# HR_C7000_DM32 register map
Vendor: Dahua Technology (chip); Baofeng (radio product); Series: HR_C7000; File version: 0.1-dm32re-draft
CPU: other r0p0, little endian, no MPU, no FPU, 0 interrupt priority bits
Registers are 32-bit, read-write, reset 0x0 unless marked. A register's access mark holds for its fields unless they carry their own. Offsets are from the block's base; [hi:lo] are bit positions; {n}, {i} and the like mark numbered series; <NAME> marks a mode.

## SystemControl — Baseband/modem system control and clock manager, 64 KB window at 0x11000000 (memory map, v2.2 manual p.10). Registers from several datasheet chapters share this window: soft reset (DS §4.1), clock manager (§4.2), system control and pad mux (§4.4), baseband system control (§4.6, Register Table 4 p.144-146), DMR physical layer (§9.2, Register Table 27 p.490-492), DMR link layer (§10.2, Register Table 28 p.526-527) and FM (§11.2). HAND-MAINTAINED and not yet complete: the datasheet also lists IOMGR_REN_REG1 (0x44), IOMGR_IE_IE0-2 (0x4c-0x54), RTC_REQ_HOLD (0x58), RECV_INFO_COUNT (0x164), RECVFIR_COEF1-17 (0x16c-0x1ac), PHY_RECEIVE_STATE (0x1c0), LAYER2_MAX_CNT (0x410), LAYER2_BS_MODE (0x428), BS_SECOND_REG (0x430), BS_STATUS (0x434), BS_CACH (0x438), FM_SQL (0x508), USER_DEFINE_CTC (0x51c), CDCSS_ADDR (0x520), XTCSS_ADDR (0x52c), FM_FUNCTION_COEF1-8 (0x530-0x54c), FM_DECODE_FLAG1 (0x564) and FM_ADDR_SW (0x56c), which are not described here (their offsets fall inside the RESERVED gaps). Three registers (REG_0x168, REG_0x370-REG_0x37c, INTERP_CLEAR_AUX) are not in the datasheet and come from the stock firmware writing them; they are named by offset or by placeholder.
Base 0x11000000
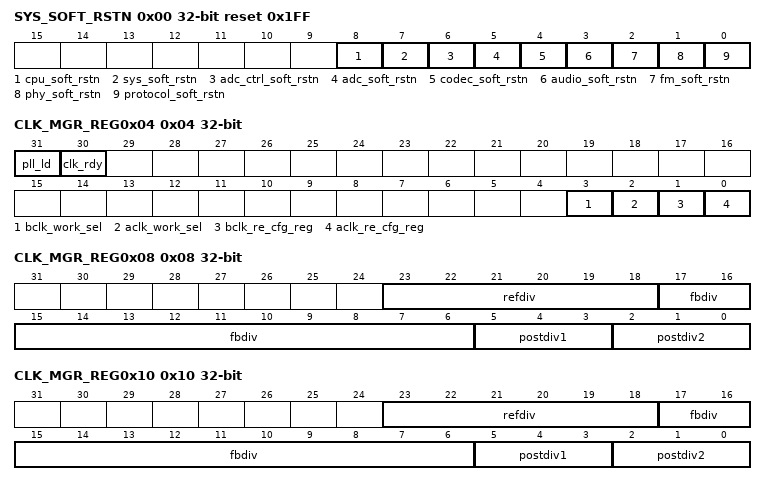
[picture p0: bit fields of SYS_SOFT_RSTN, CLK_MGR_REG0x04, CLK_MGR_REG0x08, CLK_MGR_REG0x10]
0x00 SYS_SOFT_RSTN reset 0x1FF — Per-module soft reset. DS §4.1.4.1 p.70. Writing 0 to a bit resets that module; the bit then returns to 1 by itself (self-clearing pulse, DS §4.1.2).
  [8] cpu_soft_rstn — CPU soft reset, low-active, self-clearing
  [7] sys_soft_rstn — System global soft reset, low-active, self-clearing
  [6] adc_ctrl_soft_rstn — Built-in CPU IP ADC soft reset, low-active, self-clearing
  [5] adc_soft_rstn — Built-in baseband IP ADC soft reset, low-active, self-clearing
  [4] codec_soft_rstn — Built-in IP CODEC soft reset, low-active, self-clearing
  [3] audio_soft_rstn — Audio interface module soft reset, low-active, self-clearing
  [2] fm_soft_rstn — FM module soft reset, low-active, self-clearing
  [1] phy_soft_rstn — Physical layer module soft reset, low-active, self-clearing
  [0] protocol_soft_rstn — Protocol layer module soft reset, low-active, self-clearing
0x04 CLK_MGR_REG0x04 — Top-level PLL / clock-switch control. DS §4.2.5.1 p.78. The stock boot clock init (IRAM 0x12480) busy-waits until bits [31:30] read 1 (dm32uv-qemu hw/misc/dm32_sysreg.c models this).
  [31] pll_ld ro — Combined PLL-A/PLL-B lock flag (RO)
  [30] clk_rdy ro — Clock-switch-ready flag (RO)
  [3] bclk_work_sel — SOC system clock source select: 0=PLL, 1=oscillator (default: oscillator)
  [2] aclk_work_sel — Baseband/modem system clock source select: 0=PLL, 1=oscillator
  [1] bclk_re_cfg_reg — SOC system PLL reconfiguration-ready flag, set by CPU
  [0] aclk_re_cfg_reg — Baseband/modem PLL reconfiguration-ready flag, set by CPU
0x08 CLK_MGR_REG0x08 — APLL configuration. DS §4.2.5.2 p.79. The divider fields below are transcribed; the lock, power-down, DSM/DAC power-down and bypass bits in [31:24] are not yet transcribed here.
  [23:18] refdiv — APLL reference divider (default 0x1)
  [17:6] fbdiv — APLL feedback divider (default 0x3a = 58)
  [5:3] postdiv1 — APLL post-divider 1 (default 0x6)
  [2:0] postdiv2 — APLL post-divider 2 (default 0x2)
0x0C CLK_MGR_REG0x0c reset 0xFB7E91 — APLL fractional divider (apll_frac). DS §4.2.5.3 p.81.
  [23:0] apll_frac — APLL fractional-mode divider value
0x10 CLK_MGR_REG0x10 — BPLL configuration, same layout as CLK_MGR_REG0x08. DS §4.2.5.4 p.81. Upper control bits not yet transcribed here.
  [23:18] refdiv — BPLL reference divider (default 0x2)
  [17:6] fbdiv — BPLL feedback divider (default 0x28 = 40)
  [5:3] postdiv1 — BPLL post-divider 1 (default 0x2)
  [2:0] postdiv2 — BPLL post-divider 2 (default 0x2)
0x14 CLK_MGR_REG0x14 — BPLL fractional divider (bpll_frac). DS §4.2.5.5 p.82.
  [23:0] bpll_frac — BPLL fractional-mode divider value
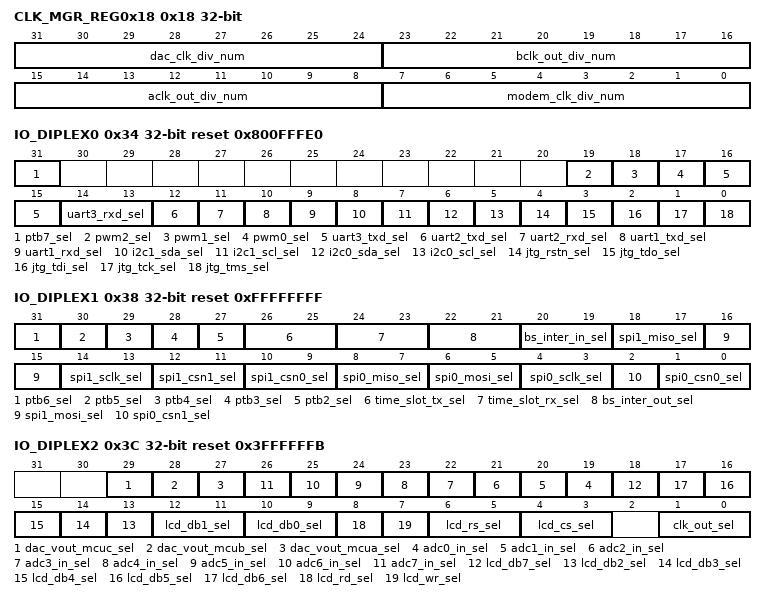
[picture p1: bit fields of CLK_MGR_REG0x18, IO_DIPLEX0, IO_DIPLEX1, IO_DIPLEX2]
0x18 CLK_MGR_REG0x18 — Per-domain output clock divider numerators. DS §4.2.5.6 p.83.
  [31:24] dac_clk_div_num — DAC clock divider numerator (default 0x10)
  [23:16] bclk_out_div_num — SOC output clock divider numerator (default 0xa)
  [15:8] aclk_out_div_num — Baseband/modem output clock divider numerator (default 0xc)
  [7:0] modem_clk_div_num — Modem clock divider numerator (default 0xc)
0x1C CLK_MGR_REG0x1c — Fractional dividers for the 32 kHz and 192 kHz clocks (denominator/numerator pairs). DS §4.2.5.7 p.83. Bit ranges not yet transcribed here; no fields defined.
0x20 CLK_MGR_REG0x20 — Codec MCLK source select (mclk_sel_reg) and divider (mclk_div_num: 24 MHz / (mclk_div_num + 1)), plus the 8 kHz and 512 kHz fractional dividers. DS §4.2.5.8 p.83. Bit ranges not yet transcribed here.
0x24 CLK_MGR_REG0x24 — CPU-side DAC/ADC clock dividers, SDIO clock delay tuning (sdio_clk_dly_reg_drv/_sample), AHB:APB ratio (apb_clk_div_num: 0 = 1:1, 1 = 1:2, 2 = 1:4) and AHB:CPU ratio (cpu_clk_ratio_reg: 0 = 1:1, 1 = 1:2). DS §4.2.5.9 p.84. Bit positions not yet transcribed here.
0x28 CLK_MGR_REG0x28 — SDIO clock divider (from a doubled 96 MHz clock) and USB 48 MHz divider. DS §4.2.5.10 p.85. Bit ranges not yet transcribed here.
0x2C CLK_MGR_REG0x2c — Clock-gate enables. DS §4.2.5.11 p.86. Field names: dac_clk_en, adc_clk_en, hclk_en, pclk_en, sdio_hclk_en, sdio_clk_en, usb_hclk_en, usb_clk_en, mc_clk_en, modem_clk_rx_en, modem_clk_tx_en, modem_clk_fmrx_en, modem_clk_fmtx_en, clk_512k_en_reg, clk_8k_en_reg, bclk_out_en_reg, aclk_out_en_reg. Bit positions not yet transcribed here.
0x30 LCSFC_BAUDR — Program-flash controller (LCSFC) SPI SCLK divider, lcsfc_baudr [31:0], reset 0x4. DS §4.4.4.1 p.93.
0x34 IO_DIPLEX0 reset 0x800FFFE0 — Pad multiplexing, bank 0: JTAG, I2C0/1, UART1-3, PWM0-2 and PTB7 (AK codec ADC_SDO) pads. DS §4.4.4.4 p.93. General rule (DS §4.4.4.4-4.4.4.6): each field's all-ones value selects the pad's GPIO function (GPIO_PTxN = bank x, bit N) and each field resets to it, except the five JTAG selects [4:0], which reset to 0 = JTAG; setting them loses the JTAG port. A pad must be switched away from GPIO before its peripheral sees it.
  [31] ptb7_sel — PTB7 multiplexing selection. 1: GPIO1_PTB7; 0: AK_ADC_SDO. (GPIO1_PTB7 = GPIOB bit 7.) [reset 0x1]
  [19] pwm2_sel — PWM_2 multiplexing selection. 1: GPIO_PTA17; 0: PWM_2 [reset 0x1]
  [18] pwm1_sel — PWM_1 multiplexing selection. 1: GPIO_PTA16; 0: PWM_1 [reset 0x1]
  [17] pwm0_sel — PWM_0 multiplexing selection. 1: GPIO_PTA15; 0: PWM_0 [reset 0x1]
  [16:15] uart3_txd_sel — UART3_TXD multiplexing selection. 3: GPIO_PTA14; 2: Reserved; 1: Baseband rf_rx_inter; 0: UART3_TXD [reset 0x3]
  [14:13] uart3_rxd_sel — UART3_RXD multiplexing selection. 3: GPIO_PTA13; 2: Reserved; 1: Baseband rf_tx_inter; 0: UART3_RXD [reset 0x3]
  [12] uart2_txd_sel — UART2_TXD multiplexing selection. 1: GPIO_PTA12; 0: UART2_TXD [reset 0x1]
  [11] uart2_rxd_sel — UART2_RXD multiplexing selection. 1: GPIO_PTA11; 0: UART2_RXD [reset 0x1]
  [10] uart1_txd_sel — UART1_TXD multiplexing selection. 1: GPIO_PTA10; 0: UART1_TXD [reset 0x1]
  [9] uart1_rxd_sel — UART1_RXD multiplexing selection. 1: GPIO_PTA9; 0: UART1_RXD [reset 0x1]
  [8] i2c1_sda_sel — I2C_SDA_1 multiplexing selection. 1: GPIO_PTA8; 0: I2C_SDA_1 [reset 0x1]
  [7] i2c1_scl_sel — I2C_SCL_1 multiplexing selection. 1: GPIO_PTA7; 0: I2C_SCL_1 [reset 0x1]
  [6] i2c0_sda_sel — I2C_SDA_0 multiplexing selection. 1: GPIO_PTA6; 0: I2C_SDA_0 [reset 0x1]
  [5] i2c0_scl_sel — I2C_SCL_0 multiplexing selection. 1: GPIO_PTA5; 0: I2C_SCL_0 [reset 0x1]
  [4] jtg_rstn_sel — JTG_RST_N multiplexing selection. 1: GPIO_PTA4; 0: JTG_RST_N [reset 0x0]
  [3] jtg_tdo_sel — JTG_TDO multiplexing selection. 1: GPIO_PTA3; 0: JTG_TDO [reset 0x0]
  [2] jtg_tdi_sel — JTG_TDI multiplexing selection. 1: GPIO_PTA2; 0: JTG_TDI [reset 0x0]
  [1] jtg_tck_sel — JTG_TCK multiplexing selection. 1: GPIO_PTA1; 0: JTG_TCK [reset 0x0]
  [0] jtg_tms_sel — JTG_TMS multiplexing selection. 1: GPIO_PTA0; 0: JTG_TMS [reset 0x0]
0x38 IO_DIPLEX1 reset 0xFFFFFFFF — Pad multiplexing, bank 1: SPI0/SPI1 (with SDIO alternates), the baseband TIME_SLOT/BS_INTER lines and PTB2-PTB6 (AK codec ADC/DAC serial pads). DS §4.4.4.5 p.97. FW: hr_c7000_modem_core_clock_and_reset_init @0x0301d5f8 sets bits 27-29 (|= 0x38000000: PTB2-PTB4 to GPIO).
  [31] ptb6_sel — PTB6 multiplexing selection. 1: GPIO1_PTB6; 0: AK_ADC_SCLK [reset 0x1]
  [30] ptb5_sel — PTB4 multiplexing selection. 1: GPIO1_PTB5; 0: AK_ADC_FS. The guide prints this row's name as 'PTB4', a typo for PTB5 (the GPIO it selects is PTB5). [reset 0x1]
  [29] ptb4_sel — PTB4 multiplexing selection. 1: GPIO1_PTB4; 0: AK_DAC_SDI [reset 0x1]
  [28] ptb3_sel — PTB3 multiplexing selection. 1: GPIO1_PTB3; 0: AK_DAC_SCLK [reset 0x1]
  [27] ptb2_sel — PTB2 multiplexing selection. 1: GPIO1_PTB2; 0: AK_DAC_FS [reset 0x1]
  [26:25] time_slot_tx_sel — TIME_SLOT_T_INTER multiplexing selection. 3: GPIO_PTA31; 2: SDIO sdio_card_write_prt; 1: Reserved; 0: TIME_SLOT_T_INTER [reset 0x3]
  [24:23] time_slot_rx_sel — TIME_SLOT_R_INTER multiplexing selection. 3: GPIO_PTA30; 2: SDIO sdio_card_detect_n; 1: Reserved; 0: TIME_SLOT_R_INTER [reset 0x3]
  [22:21] bs_inter_out_sel — BS_INTER_OUT multiplexing selection. 3: GPIO_PTA29; 2: SDIO sdio_cdata[1]; 1: Reserved; 0: BS_INTER_OUT [reset 0x3]
  [20:19] bs_inter_in_sel — BS_INTER_IN multiplexing selection. 3: GPIO_PTA28; 2: SDIO sdio_cdata[2]; 1: POR_RST_N; 0: BS_INTER_IN [reset 0x3]
  [18:17] spi1_miso_sel — SPI1_MISO multiplexing selection. 3: GPIO_PTA27; 2: SDIO sdio_cdata[0]; 1: Slave SPI1_MISO; 0: Master SPI1_MISO [reset 0x3]
  [16:15] spi1_mosi_sel — SPI1_MOSI multiplexing selection. 3: GPIO_PTA26; 2: SDIO sdio_ccmd; 1: Slave SPI1_MOSI; 0: Master SPI1_MOSI [reset 0x3]
  [14:13] spi1_sclk_sel — SPI1_SCLK multiplexing selection. 3: GPIO_PTA25; 2: SDIO sdio_cclk_out; 1: Slave SPI1_SCLK; 0: Master SPI1_SCLK [reset 0x3]
  [12:11] spi1_csn1_sel — SPI1_CSN_1 multiplexing selection. 3: GPIO_PTA24; 2: Reserved; 1: Baseband sys_inter; 0: Master SPI1_CSN_1 [reset 0x3]
  [10:9] spi1_csn0_sel — SPI1_CSN_0 multiplexing selection. 3: GPIO_PTA23; 2: SDIO sdio_cdata[3]; 1: Slave SPI1_CSN_0; 0: Master SPI1_CSN_0 [reset 0x3]
  [8:7] spi0_miso_sel — SPI0_MISO multiplexing selection. 3: GPIO_PTA22; 2: Reserved; 1: Slave SPI0_MISO; 0: Master SPI0_MISO [reset 0x3]
  [6:5] spi0_mosi_sel — SPI0_MOSI multiplexing selection. 3: GPIO_PTA21; 2: Reserved; 1: Slave SPI0_MOSI; 0: Master SPI0_MOSI [reset 0x3]
  [4:3] spi0_sclk_sel — SPI0_SCLK multiplexing selection. 3: GPIO_PTA20; 2: Reserved; 1: Slave SPI0_SCLK; 0: Master SPI0_SCLK [reset 0x3]
  [2] spi0_csn1_sel — SPI0_CSN_1 multiplexing selection. 1: GPIO_PTA19; 0: SPI0_CSN_1 [reset 0x1]
  [1:0] spi0_csn0_sel — SPI0_CSN_0 multiplexing selection. 3: GPIO_PTA18; 2: Reserved; 1: Slave SPI0_CSN_0; 0: Master SPI0_CSN_0 [reset 0x3]
0x3C IO_DIPLEX2 reset 0x3FFFFFFB — Pad multiplexing, bank 2: CLK_OUT, the LCD bus (CS/RS/WR/RD, DB0-DB7; CS/RS/DB0/DB1 also SPI2), ADC0-7 inputs and DAC_VOUT_MCUA-C. DS §4.4.4.6 p.101. FW: every stock keypad scan (keypad_scan_and_map_pressed_key @0x03013660) first calls 0x03012e14, which sets IO_DIPLEX2 |= 0xfe00 (LCD_DB0-DB4 pads = GPIOC 7-11 to GPIO, to drive the keypad lines); lcd_bus_restore_after_keypad_scan @0x0301cad0 undoes it with &= 0xffff01ff, and the panel init lcd_controller_power_on_init_sequence @0x03017d4c claims the panel pads with &= 0xfff80107 (literal at 0x03017f4c). An LCD write while DB0-DB4 are muxed to GPIO misses the panel (observed on hardware: the panel stays white until power-cycled).
  [29] dac_vout_mcuc_sel — DAC_VOUT_MCUC multiplexing selection. 1: GPIO_PTC25; 0: DAC_VOUT_MCUC [reset 0x1]
  [28] dac_vout_mcub_sel — DAC_VOUT_MCUB multiplexing selection. 1: GPIO_PTC24; 0: DAC_VOUT_MCUB [reset 0x1]
  [27] dac_vout_mcua_sel — DAC_VOUT_MCUA multiplexing selection. 1: GPIO_PTC23; 0: DAC_VOUT_MCUA [reset 0x1]
  [n+19] adc{n}_in_sel (n=0..7) — ADC{n}_IN multiplexing selection. 1: GPIO_PTC{n+15}; 0: ADC{n}_IN [reset 0x1]
  [18] lcd_db7_sel — LCD_DB7 multiplexing selection. 1: GPIO_PTC24; 0: LCD_DB7. The guide prints GPIO_PTC24, which bit 28 also claims; the pattern of the neighbouring rows gives GPIO_PTC14 (INFERRED). [reset 0x1]
  [n+11] lcd_db{n}_sel (n=2..6) — LCD_DB{n} multiplexing selection. 1: GPIO_PTC{n+7}; 0: LCD_DB{n} [reset 0x1]
  [12:11] lcd_db1_sel — LCD_DB1 multiplexing selection. 3: GPIO_PTC8; 2: Slave SPI2_MOSI; 1: Master SPI2_MOSI; 0: LCD_DB1 [reset 0x3]
  [10:9] lcd_db0_sel — LCD_DB0 multiplexing selection. 3: GPIO_PTC7; 2: Slave SPI2_MISO; 1: Master SPI2_MISO; 0: LCD_DB0 [reset 0x3]
  [8] lcd_rd_sel — LCD_RD multiplexing selection. 1: GPIO_PTC6; 0: LCD_RD [reset 0x1]
  [7] lcd_wr_sel — LCD_WR multiplexing selection. 1: GPIO_PTC5; 0: LCD_WR [reset 0x1]
  [6:5] lcd_rs_sel — LCD_RS multiplexing selection. 3: GPIO_PTC4; 2: Slave SPI2_SCLK; 1: Master SPI2_SCLK; 0: LCD_RS [reset 0x3]
  [4:3] lcd_cs_sel — LCD_CS multiplexing selection. 3: GPIO_PTC3; 2: Slave SPI2_CS; 1: Master SPI2_CS; 0: LCD_CS [reset 0x3]
  [1:0] clk_out_sel — CLK_OUT multiplexing selection. 3: GPIO_PTC0; 2: RTC_CLK; 1: PLLB CLK_OUT; 0: PLLA CLK_OUT [reset 0x3]
0x40 RESERVED_0x40 — The datasheet's IOMGR_REN_REG0 (pad pull-up enables, 1 = pull-up off, 0 = on; DS §4.4.4.7 p.105), kept under this placeholder name so existing decompiler labels stay stable; fields not transcribed here. FW: hr_c7000_modem_core_clock_and_reset_init @0x0301d5f8 clears bit 24 (spi1_csn1_ren: pull-up on) and sets bit 25 (spi1_sclk_ren: off) right after its IO_DIPLEX1 write.
0x48 RESERVED_0x48 — The datasheet's IOMGR_REN_REG2 (pad pull-up enables for PTB pads, 1 = pull-up off; DS §4.4.4.9 p.113), kept under this placeholder name; fields not transcribed here. FW: the same function as RESERVED_0x40 sets bits 27 and 26 (ptb27_ren, ptb26_ren: pull-ups off).
0x5C QUAD_ENABLE — Program-flash controller quad mode: quad_enable [0] (four-wire enable, high active) and sys_sample_delay [31:24] (input sampling delay, 0-8). DS §4.4.4.3 p.93. Fields not transcribed here.
0x70 DAC_CONTROL — Baseband DAC control (power-down, low-power mode, data format). DS §4.6.5.1 p.146. Fields not transcribed here.
0x74 ADC_CONTROL — Baseband ADC control. DS §4.6.5.2 p.146. Fields not transcribed here.
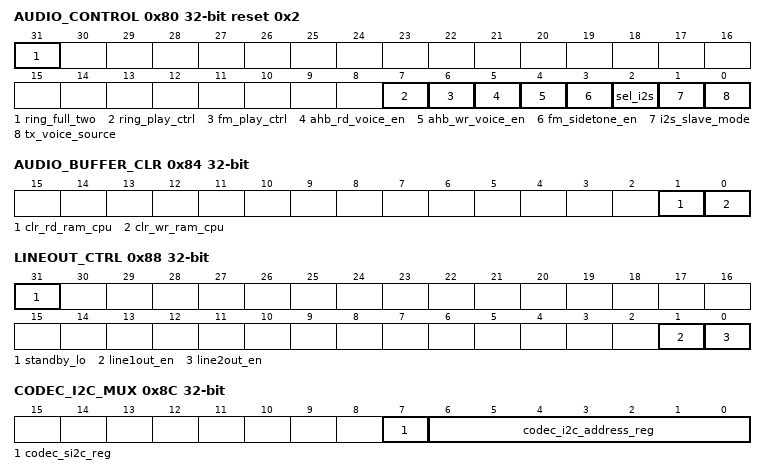
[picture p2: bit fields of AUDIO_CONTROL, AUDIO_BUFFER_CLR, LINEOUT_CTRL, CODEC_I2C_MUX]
0x80 AUDIO_CONTROL reset 0x2 — Audio path routing. DS §4.6.5.3 p.148. The stock firmware's bit-mask writes match these field names.
  [31] ring_full_two ro — Prompt-tone PCM FIFO full flag (RO); stop writing until it clears
  [7] ring_play_ctrl — Select prompt/alert-tone path, high-active
  [6] fm_play_ctrl — Select FM playback channel, high-active
  [5] ahb_rd_voice_en — AHB read-audio enable, high-active
  [4] ahb_wr_voice_en — AHB write-audio start flag, high-active
  [3] fm_sidetone_en — Analog sidetone playback enable, high-active
  [2] sel_i2s — I2S interface enable (baseband test mode)
  [1] i2s_slave_mode — Audio I2S master/slave: 0=master, 1=slave (baseband test mode). Default 1.
  [0] tx_voice_source — Voice-frame source select: 0=Codec/vocoder (normal handheld use), 1=MCU RAM (Layer-2 BS send mode)
0x84 AUDIO_BUFFER_CLR — Vocoder encode/decode buffer clear. DS §4.6.5.4 p.150. Both bits are write-1-to-clear and release themselves.
  [1] clr_rd_ram_cpu — Write 1 to clear the vocoder DECODE buffer; self-clears
  [0] clr_wr_ram_cpu — Write 1 to clear the vocoder ENCODE buffer; self-clears
0x88 LINEOUT_CTRL — Codec line-out enables. DS §4.6.5.5 p.150.
  [31] standby_lo ro — Line-out standby status (RO)
  [1] line1out_en — Line-out 1 enable
  [0] line2out_en — Line-out 2 enable
0x8C CODEC_I2C_MUX — Codec control-interface select. DS §4.6.5.6 p.150.
  [7] codec_si2c_reg — Codec control interface select: 0=MC interface, 1=I2C
  [6:0] codec_i2c_address_reg — Codec I2C address (when codec_si2c_reg=1)
0x100 WORK_MODE — Baseband working mode: digital/analog, Tier I/II, continuous/timeslot, layer mode [4:3] (0 physical, 1 layer 2, 2 layer 3), repeater, alignment, working slot. DS §4.6.5.7 p.151, §9.2.2.1 p.492 (the DMR and FM chapters repeat it). Fields not transcribed here. An emulator trace (dm32uv-qemu hw/misc/dm32_sysreg.c) saw (value & 0x18) != 0, i.e. a non-physical layer mode, when the modem entered active free-run establishment in a TX-slot self-test.
0x104 RF_MODE — Baseband RF interface mode. DS §4.6.5.8 p.152, §9.2.2.2 p.494. Fields not transcribed here.
0x108 SIG_CENTER — TX/RX IQ DC-bias setting. FW: mmio_11000108_high_word_write_from_byte @0x0302180c writes a repeated byte into the upper 16 bits (param << 24 | (param & 0xff) << 16). DS §9.2.2.3 p.496.
0x10C TX_IF_FREQ — TX IF frequency word. FW: hr_c7000_modem_core_register_init @0x03023608. DS §9.2.2.4 p.497.
0x110 RF_CONTROL — RF TX/RX interrupt advance. FW: modem_rf_mode_transition_apply @0x0301e628 ORs in 0x1a00 then 0x12, next to an RF_MODE |= 0x800 write, in one RF-mode branch. DS §9.2.2.5 p.498.
0x114 RF_MOD_BIAS_CTRL — TX signal amplitude adjustment. FW: mmio_11000114_low_word_duplicate_write @0x03021830 writes (param & 0xff) * 0x101 into the low 16 bits. DS §9.2.2.6 p.498.
0x118 DEV_LIMITER — TX frequency-deviation threshold. FW: hr_c7000_modem_core_register_init @0x03023608, FUN_00016b60. DS §9.2.2.7 p.498.
0x11C RSSI_BIAS_VALUE — Signal-energy detection value and ADC DC-bias detection. FW: hr_c7000_modem_core_register_init @0x03023608, FUN_030c6780. DS §9.2.2.8 p.498.
0x120 THRESHOLD_VALUE — Sync-detection threshold. FW: hr_c7000_modem_core_register_init @0x03023608. DS §9.2.2.9 p.499.
0x128 PHASE_OUT — Phase-input amplitude detection in AF receive mode. DS §9.2.2.10 p.500.
0x12C SEND_DATA_SYNC_H — TX data sync pattern, high half. FW: modem_rf_mode_transition_apply @0x0301e628 loads SEND_DATA_SYNC_H/L as a pair from one of two 2-word tables (literal-pool slots 0x0301e890 and 0x0301e738), depending on the mode. DS §9.2.2.11 p.500.
0x130 SEND_DATA_SYNC_L — TX data sync pattern, low half (see SEND_DATA_SYNC_H). DS §9.2.2.12 p.500.
0x134 SEND_RC_SYNC_H — TX RC (reverse channel) sync pattern, high half. DS §9.2.2.13 p.502.
0x138 SEND_RC_SYNC_L — TX RC sync pattern, low half. DS §9.2.2.14 p.502.
0x13C RECV_MS_SYNC_H — RX MS data sync pattern, high half. DS §9.2.2.15 p.502.
0x140 RECV_MS_SYNC_L — RX MS data sync pattern, low half. DS §9.2.2.16 p.502.
0x144 RECV_BS_SYNC_H — RX BS data sync pattern, high half. DS §9.2.2.17 p.503.
0x148 RECV_BS_SYNC_L — RX BS data sync pattern, low half. DS §9.2.2.18 p.504.
0x14C RECV_TDMA1_SYNC_H — RX TDMA1 data sync pattern, high half. DS §9.2.2.19 p.504.
0x150 RECV_TDMA1_SYNC_L — RX TDMA1 data sync pattern, low half. DS §9.2.2.20 p.504.
0x154 RECV_TDMA2_SYNC_H — RX TDMA2 data sync pattern, high half. DS §9.2.2.21 p.505.
0x158 RECV_TDMA2_SYNC_L — RX TDMA2 data sync pattern, low half. DS §9.2.2.22 p.506.
0x15C RECV_RC_SYNC_H — RX RC data sync pattern, high half. DS §9.2.2.23 p.506.
0x160 RECV_RC_SYNC_L — RX RC data sync pattern, low half. DS §9.2.2.24 p.506.
0x168 REG_0x168 — Not in the datasheet: Register Table 27 (DS §9.2.1 p.490-492) goes from RECV_INFO_COUNT (0x164) to RECVFIR_COEF1 (0x16c), and no edition lists 0x168. Its existence comes from the stock firmware, which writes it: hr_c7000_modem_core_register_init @0x03023608 stores 0x14 (0x03023760) when the RF mode is 4 and 0x98 (0x030237ba) otherwise, and radio_mode_transition_sequencer @0x03021670 stores 0x98 (0x0302172c); each store is paired with an RF_RECV_DELAY write (14000 or 0). A third-party driver header lists the same offset without a name. Role unknown; named by offset.
0x1B0 RX_IF_FREQ — RX IF frequency word. DS §9.2.2.43 p.515.
0x1B4 RF_RECV_DELAY — RX channel delay offset. FW: written with REG_0x168 (14000 in RF mode 4, else 0). DS §9.2.2.44 p.515.
0x1B8 MODEM_AK_CLK_CALB — AK2401 clock adjustment control. The section prints offset 0x1b4 (RF_RECV_DELAY's); Register Table 27 gives 0x1b8, which is used. DS §9.2.2.45 p.515.
0x1BC AK2401_ADC_STATE — AK2401 ADC receive status. DS §9.2.2.46 p.516.
0x350 PI_CRC_MASK — PI frame CRC16 mask and initial value. FW: register_init @0x03023608 writes 0x6969. DS §10.2.2.2 p.529.
0x354 RS_H_MASK — RS(12,9) code mask for the voice LC header. DS §10.2.2.3 p.529.
0x358 RS_H_INIT — RS code initial value for the voice LC header. FW: register_init writes 0. DS §10.2.2.4 p.530.
0x35C RS_T_MASK — RS code mask for the terminator. DS §10.2.2.5 p.531.
0x360 RS_T_INIT — RS code initial value for the terminator. FW: register_init writes 0. DS §10.2.2.6 p.531.
0x364 CSBK_CRC_MASK — CSBK CRC16 mask and initial value. FW: register_init writes 0xa5a5. DS §10.2.2.7 p.531.
0x368 MBCH_CRC_MASK — MBC header CRC16 mask and initial value. FW: register_init writes 0xaaaa. DS §10.2.2.8 p.531.
0x36C DATAH_CRC_MASK — Data header CRC16 mask and initial value. FW: register_init writes 0xcccc. DS §10.2.2.9 p.531.
0x370 REG_0x370 — Not in the datasheet: Register Table 28 (DS §10.2.1 p.526-527) goes from DATAH_CRC_MASK (0x36c) to CRC8_INIT (0x380), and no edition lists 0x370-0x37c. Its existence comes from the stock firmware: hr_c7000_modem_core_register_init @0x03023608 stores 0xf0 here (st32.w at 0x030236d2), in the same run of stores that initialises the CRC mask registers around it (0x370 = 0xf0, 0x374 = 0x1ff, 0x378 = 0x10f, 0x37c = 0). A third-party driver header lists 0x370-0x37c as unnamed ('???'). Role unknown; named by offset.
0x374 REG_0x374 — Not in the datasheet: Register Table 28 (DS §10.2.1 p.526-527) goes from DATAH_CRC_MASK (0x36c) to CRC8_INIT (0x380), and no edition lists 0x370-0x37c. Its existence comes from the stock firmware: hr_c7000_modem_core_register_init @0x03023608 stores 0x1ff here (st32.w at 0x030236da), in the same run of stores that initialises the CRC mask registers around it (0x370 = 0xf0, 0x374 = 0x1ff, 0x378 = 0x10f, 0x37c = 0). A third-party driver header lists 0x370-0x37c as unnamed ('???'). Role unknown; named by offset.
0x378 REG_0x378 — Not in the datasheet: Register Table 28 (DS §10.2.1 p.526-527) goes from DATAH_CRC_MASK (0x36c) to CRC8_INIT (0x380), and no edition lists 0x370-0x37c. Its existence comes from the stock firmware: hr_c7000_modem_core_register_init @0x03023608 stores 0x10f here (st32.w at 0x030236e2), in the same run of stores that initialises the CRC mask registers around it (0x370 = 0xf0, 0x374 = 0x1ff, 0x378 = 0x10f, 0x37c = 0). A third-party driver header lists 0x370-0x37c as unnamed ('???'). Role unknown; named by offset.
0x37C REG_0x37c — Not in the datasheet: Register Table 28 (DS §10.2.1 p.526-527) goes from DATAH_CRC_MASK (0x36c) to CRC8_INIT (0x380), and no edition lists 0x370-0x37c. Its existence comes from the stock firmware: hr_c7000_modem_core_register_init @0x03023608 stores 0 here (st32.w at 0x030236e6), in the same run of stores that initialises the CRC mask registers around it (0x370 = 0xf0, 0x374 = 0x1ff, 0x378 = 0x10f, 0x37c = 0). A third-party driver header lists 0x370-0x37c as unnamed ('???'). Role unknown; named by offset.
0x380 CRC8_INIT — Short LC CRC8 initial value. FW: register_init writes 0. DS §10.2.2.10 p.533.
0x384 LOCAL_CC — Local colour code for TX and RX, voice-frame EMB PI setting. DS §10.2.2.11 p.533.
0x388 VOICE_EMB_CTRL — Voice frame F EMB fill settings. FW: register_init writes 0. DS §10.2.2.12 p.533.
0x38C SCRAMBLE_REG — Basic voice-scrambling key. FW: register_init writes 0. DS §10.2.2.13 p.534.
0x390 RX_TYPE_INFO — Received frame information. DS §10.2.2.14 p.535.
0x394 RX_INFO — Received RC frame information. Register Table 28 prints offset 0x39c (SYS_INTERP_MASK's); the section gives 0x394, which is used. DS §10.2.2.15 p.537.
0x398 SYS_INTERP_LIST — System (layer-2) interrupt vector list: L2 TX/RX processing, voice access, frame info, slot faults, simulcast GPS-pulse loss, FM detect/RX/TX. The bit numbering is in the datasheet but not transcribed here. DS §4.6.5.9 p.156.
0x39C SYS_INTERP_MASK — Mask for SYS_INTERP_LIST. FW: register_init @0x03023608 writes 0x1187f. DS §4.6.5.10 p.156.
0x3A0 SYS_INTERP_CLEAR — Clear for SYS_INTERP_LIST (write 1 to clear). DS §4.6.5.11 p.160.
0x3A4 LAYER3_INTERP_LIST — Layer-3 interrupt vector list: call reject/timeout, OACSU, voice TX start/end/EMB/key update, SMS TX/RX (CRC32 error/ok), repeater short LC. Bit numbering not transcribed here. DS §4.6.5.12 p.160.
0x3A8 LAYER3_INTERP_MASK — Mask for LAYER3_INTERP_LIST. DS §4.6.5.13 p.162.
0x3AC LAYER3_INTERP_CLEAR — Clear for LAYER3_INTERP_LIST. DS §4.6.5.14 p.165.
0x3B0 INTERP_CLEAR — Clear for the 30 ms, RF and PCM interrupts. DS §4.6.5.15 p.166. Bit 0 is transcribed; the datasheet gives seven fields. FW: the TX-slot ISR (IRAM 0x2c42c) writes bit 0 before posting its semaphore (also modelled in dm32uv-qemu hw/misc/dm32_sysreg.c).
  [0] clear_time_txslot_inter — Write 1 to acknowledge/clear the TX-slot-wrap interrupt (PIC source 30)
0x3B4 INTERP_CLEAR_AUX — Not in the datasheet (Register Table 4 ends at INTERP_CLEAR, 0x3b0) and not in any third-party header; placeholder name. FW: written with the fixed value 0x1800 by at least 11 functions of the cps_serial_field_rw_* family (cps_serial_field_rw_dispatcher @0x0302aaec, its _variant and _reentry0-9), which also write INTERP_CLEAR. Role unknown.
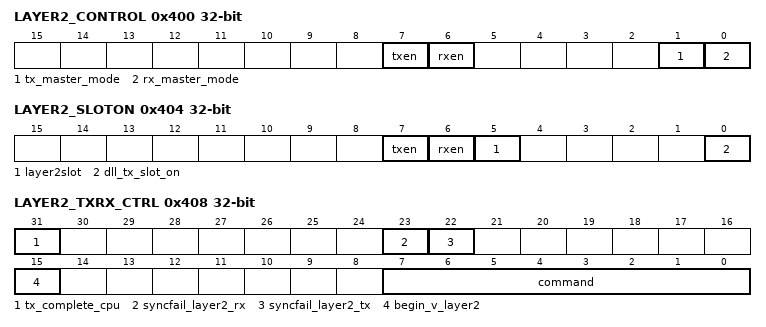
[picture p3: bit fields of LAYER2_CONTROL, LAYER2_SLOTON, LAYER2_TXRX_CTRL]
0x400 LAYER2_CONTROL — Layer-2 mode control (shared with the physical layer). DS §9.2.2.48 p.517, §10.2.2.16 p.537. Bits 0/1/6/7 transcribed. A live trace saw 0xcb during an active-establish self-test (txen, rxen, bit 4, tx_master_mode, rx_master_mode); bit 4 is not among the transcribed fields.
  [7] txen — Physical-layer TX sync enable
  [6] rxen — Physical-layer RX sync enable
  [1] tx_master_mode — 0=passive (slave/relay mode), 1=active (originating TX)
  [0] rx_master_mode — 0=passive (relay/repeat), 1=active (listening/receiving)
0x404 LAYER2_SLOTON — Layer-2 timeslot switch control. DS §10.2.2.17 p.539. Bits 0/5/6/7 transcribed.
  [7] txen — Layer-2 TX sync enable (synchronized with physical layer)
  [6] rxen — Layer-2 RX sync enable (synchronized with physical layer)
  [5] layer2slot — Current timeslot working flag: 0=non-working, 1=working. Used for smooth L2->L3 handoff when switching timeslots.
  [0] dll_tx_slot_on — 0->1 transition starts the TX-slot counter (when tx_master_mode permits)
0x408 LAYER2_TXRX_CTRL — Layer-2 TX/RX enable control (shared with the physical layer). DS §9.2.2.49 p.517, §10.2.2.18 p.541. Bits 15/22/23/31 and the low command byte transcribed; the firmware writes 0x40/0x41 to the low byte while a TX slot is established (TX keying).
  [31] tx_complete_cpu — Write-to-clear TX complete interrupt flag; cleared by hardware after RF transmission finishes
  [23] syncfail_layer2_rx — RX sync failure flag; set to force release+re-establish of RX synchronization
  [22] syncfail_layer2_tx — TX sync failure flag; set to force TX re-sync
  [15] begin_v_layer2 — Voice-frame access begin flag; set to signal Layer-2 that a voice access is starting
  [7:0] command — On-air command byte; 0x40/0x41 observed as the TX-keying trigger while a slot is established (exact full command set not enumerated)
0x40C LAYER2_SLOT_CNT — Layer-2 timeslot count initial value. DS §10.2.2.19 p.543.
0x414 LAYER2_SLOT_UPDATE — Layer-2 timeslot update settings. DS §10.2.2.21 p.544.
0x418 LAYER2_SEND_TYPE — Layer-2 TX frame type. DS §10.2.2.22 p.545.
0x41C LAYER2_STATUS ro — Layer-2 timeslot status. DS §10.2.2.23 p.549. The low 9 bits follow the live 0-287 slot counter (one DMR TDMA superframe); the firmware polls it.
  [8:0] slot_cnt — Live TDMA slot counter, cycles 0..287
0x424 LAYER2_SLOT_PRE — Pre-configured interrupt position for layer-2 processing. DS §10.2.2.24 p.549. FW: register_init @0x03023608.
0x500 FM_BANDWIDTH — FM bandwidth and filter settings. DS §11.2.2.2 p.592.
0x504 FM_DEV_COEF — FM deviation coefficient. FW: register_init @0x03023608 writes 0x33500. DS §11.2.2.3 p.594.
0x50C SUBVOICE_COEF — Sub-audio (CTCSS/CDCSS) coefficient. DS §11.2.2.5 p.594.
0x510 FM_MOD — FM modulation control. DS §11.2.2.6 p.595.
0x518 CTCSS_ADDR — CTCSS tone selection. DS §11.2.2.7 p.596.
0x524 SELCALL_TONE — Selective-call tone. DS §11.2.2.10 p.598.
0x528 TONE_SEND_CTRL — Tone transmit control. DS §11.2.2.11 p.598.
0x550 FM_TONE1 — FM tone generator 1. DS §11.2.2.21 p.602.
0x554 FM_TONE2 — FM tone generator 2. DS §11.2.2.22 p.604.
0x558 FM_TONE3 — FM tone generator 3. DS §11.2.2.23 p.604.
0x55C FM_TONE4 — FM tone generator 4. DS §11.2.2.24 p.604.
0x560 FM_PTT — FM PTT control. DS §11.2.2.25 p.604.
0x568 FM_DECODE_FLAG2 — FM decode flags 2. DS §11.2.2.27 p.605.
